# nrf54h20_engb_application register map
Vendor: Nordic Semiconductor; Series: nRF54h; File version: 1
CPU: CM33 r0p4, little endian, MPU, FPU, 3 interrupt priority bits, 480 interrupts, 8 SAU regions
Registers are 32-bit, read-write, reset 0x0 unless marked. A register's access mark holds for its fields unless they carry their own. Offsets are from the block's base; [hi:lo] are bit positions; lines under a group give offsets from that group; 'fields as' and 'values as' point back to an identical list.

## GLOBAL_TEMP_NS — Temperature Sensor 0
Base 0x4F984000
Same registers: GLOBAL_TEMP_S 0x5F984000
0x00 TASKS_START wo — Start temperature measurement
  [0] TASKS_START
    1=Trigger task
0x04 TASKS_STOP wo — Stop temperature measurement
  [0] TASKS_STOP
    1=Trigger task
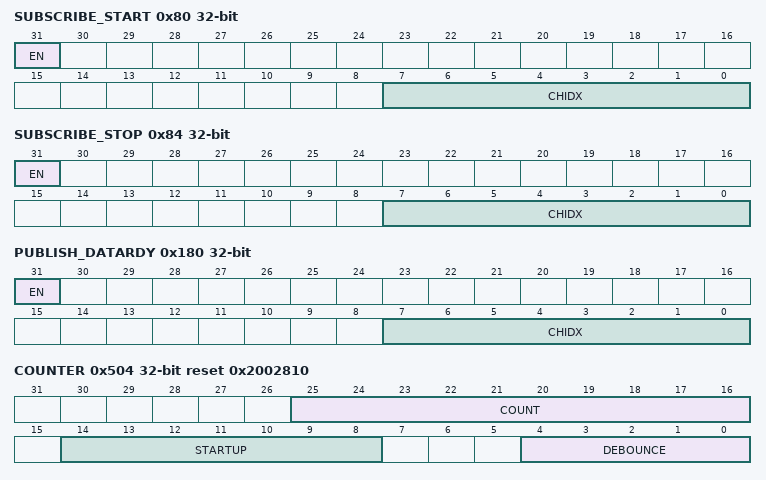
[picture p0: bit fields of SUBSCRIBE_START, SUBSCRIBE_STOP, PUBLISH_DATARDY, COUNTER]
0x80 SUBSCRIBE_START — Subscribe configuration for task START
  [31] EN
    0=Disabled (Disable subscription); 1=Enabled (Enable subscription)
  [7:0] CHIDX — DPPI channel that task START will subscribe to
0x84 SUBSCRIBE_STOP — Subscribe configuration for task STOP
  [31] EN
    values as SUBSCRIBE_START.EN
  [7:0] CHIDX — DPPI channel that task STOP will subscribe to
0x100 EVENTS_DATARDY — Temperature measurement complete, data ready
  [0] EVENTS_DATARDY
    0=NotGenerated (Event not generated); 1=Generated (Event generated)
0x180 PUBLISH_DATARDY — Publish configuration for event DATARDY
  [31] EN
    0=Disabled (Disable publishing); 1=Enabled (Enable publishing)
  [7:0] CHIDX — DPPI channel that event DATARDY will publish to
0x300 INTEN — Enable or disable interrupt
  [0] DATARDY — Enable or disable interrupt for event DATARDY
    0=Disabled; 1=Enabled
0x304 INTENSET — Enable interrupt
  [0] DATARDY — Write '1' to enable interrupt for event DATARDY
    on read: 0=Disabled (Read: Disabled); 1=Enabled (Read: Enabled) | on write: 1=Set (Enable)
0x308 INTENCLR — Disable interrupt
  [0] DATARDY — Write '1' to disable interrupt for event DATARDY
    on read: 0=Disabled (Read: Disabled); 1=Enabled (Read: Enabled) | on write: 1=Clear (Disable)
0x500 ENABLE — Enable temperature sensor bias current
  [0] ENABLE
    0=Disabled (Bias is disabled); 1=Enabled (Bias is enabled)
0x504 COUNTER reset 0x2002810 — Prototype register containing counter values for timing
  [25:16] COUNT — Number of cycles in measurement period
  [14:8] STARTUP — Number of cycles for analog startup. Simultaneous to clock debouncing.
  [4:0] DEBOUNCE — Number of cycles for clock debouncing. Simultaneous to analog startup. Should be shorter that analog startup period
0x508 TEMP ro — Temperature in degC (0.25deg steps)
0x50C TEMPRAW ro — Counted oscillator pulses which is equivalent to temperature without calibration and linearization
  [11:0] TEMPRAW — Counted OSC pulses in defined counting period
0x510 DATA ro — Data after dec and calib
  [31:0] DATA — Data after dec and calib. 12 bits sign extended to 32 bits
0x514 CALIB reset 0xD3 — Calibration value.
  [9:0] CALIB
0x518 OVERRIDE group — Unspecified
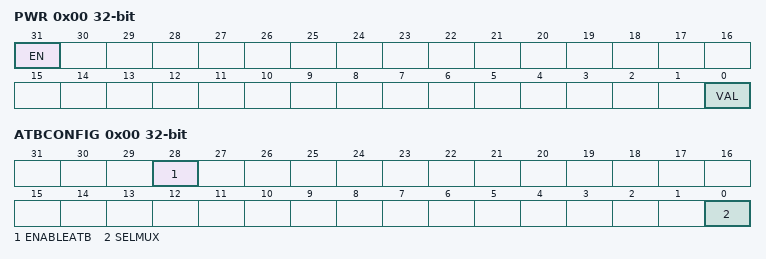
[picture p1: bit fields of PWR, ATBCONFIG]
  0x00 PWR — ANA power up override
    [31] EN — Enable the override
      0=Disabled (Override is disabled); 1=Enabled (Override is enabled)
    [0] VAL — Override value for the signal
0x520 A0 reset 0x276 — Slope of 1st piece wise linear function
  [11:0] A0
0x524 A1 reset 0x324 — Slope of 2nd piece wise linear function
  [11:0] A1
0x528 A2 reset 0x3AB — Slope of 3rd piece wise linear function
  [11:0] A2
0x52C A3 reset 0x453 — Slope of 4th piece wise linear function
  [11:0] A3
0x530 A4 reset 0x49B — Slope of 5th piece wise linear function
  [11:0] A4
0x534 A5 reset 0x550 — Slope of 6th piece wise linear function
  [11:0] A5
0x538 A6 reset 0x67E — Slope of 7th piece wise linear function
  [11:0] A6
0x540 B0 reset 0xFA6 — y-intercept of 1st piece wise linear function
  [11:0] B0
0x544 B1 reset 0xF35 — y-intercept of 2nd piece wise linear function
  [11:0] B1
0x548 B2 reset 0xFAA — y-intercept of 3rd piece wise linear function
  [11:0] B2
0x54C B3 reset 0x7E — y-intercept of 4th piece wise linear function
  [11:0] B3
0x550 B4 reset 0xEA — y-intercept of 5th piece wise linear function
  [11:0] B4
0x554 B5 reset 0x1ED — y-intercept of 6th piece wise linear function
  [11:0] B5
0x558 B6 reset 0x378 — y-intercept of 7th piece wise linear function
  [11:0] B6
0x560 T0 reset 0xED — End point of 1st piece wise linear function
  [7:0] T0
0x564 T1 reset 0x13 — End point of 2nd piece wise linear function
  [7:0] T1
0x568 T2 reset 0x29 — End point of 3rd piece wise linear function
  [7:0] T2
0x56C T3 reset 0x3C — End point of 4th piece wise linear function
  [7:0] T3
0x570 T4 reset 0x44 — End point of 5th piece wise linear function
  [7:0] T4
0x574 T5 reset 0x53 — End point of 6th piece wise linear function
  [7:0] T5
0x600 DFT group — Unspecified
  0x00 ATBCONFIG — Analog Test Bus 0-1 (ATB0-1) configuration
    [28] ENABLEATB — Enable the analog test bus 0-1 (ATB0-1)
      0=Disabled (Analog test bus is disabled); 1=Enabled (Analog test bus is enabled)
    [0] SELMUX — Select multiplexer for ATB
      0=CONFIG0 (Configuration 0 selected); 1=CONFIG1 (Configuration 1 selected)
